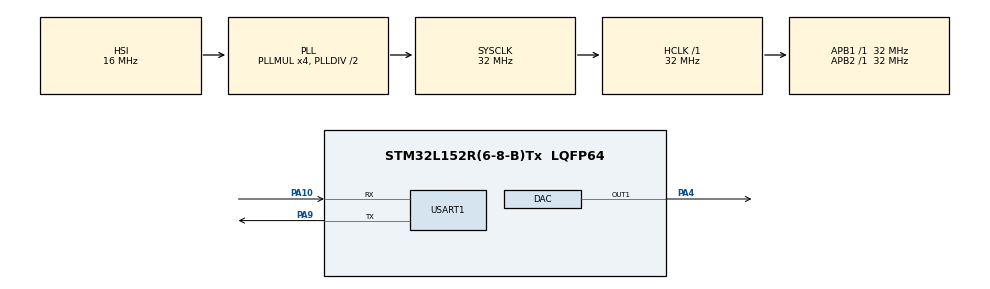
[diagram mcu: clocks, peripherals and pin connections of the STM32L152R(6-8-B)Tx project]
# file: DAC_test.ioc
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DAC.DAC_Trigger=DAC_TRIGGER_T6_TRGO
DAC.WaveGeneration=DISABLE
Dma.DAC_CH1.0.Direction=DMA_MEMORY_TO_PERIPH
Dma.DAC_CH1.0.Instance=DMA1_Channel2
Dma.DAC_CH1.0.MemDataAlignment=DMA_MDATAALIGN_HALFWORD
Dma.DAC_CH1.0.MemInc=DMA_MINC_ENABLE
Dma.DAC_CH1.0.Mode=DMA_CIRCULAR
Dma.DAC_CH1.0.PeriphDataAlignment=DMA_PDATAALIGN_HALFWORD
Dma.DAC_CH1.0.PeriphInc=DMA_PINC_DISABLE
Dma.DAC_CH1.0.Priority=DMA_PRIORITY_MEDIUM
Dma.Request0=DAC_CH1
Mcu.Family=STM32L1
Mcu.Name=STM32L152R(6-8-B)Tx
Mcu.Package=LQFP64
NVIC.DMA1_Channel2_IRQn=true\:0\:0\:false\:false\:true\:false
NVIC.PriorityGroup=NVIC_PRIORITYGROUP_4
NVIC.USART1_IRQn=true\:0\:0\:false\:false\:true\:true
PA10.Mode=Asynchronous
PA10.Signal=USART1_RX
PA13.Mode=Serial_Wire
PA13.Signal=SYS_JTMS-SWDIO
PA14.Mode=Serial_Wire
PA14.Signal=SYS_JTCK-SWCLK
PA4.Signal=COMP_DAC1_group
PA9.Mode=Asynchronous
PA9.Signal=USART1_TX
PH0-OSC_IN.Mode=HSE-External-Oscillator
PH0-OSC_IN.Signal=RCC_OSC_IN
PH1-OSC_OUT.Mode=HSE-External-Oscillator
PH1-OSC_OUT.Signal=RCC_OSC_OUT
ProjectManager.HeapSize=0x200
ProjectManager.StackSize=0x400
ProjectManager.TargetToolchain=TrueSTUDIO
RCC.48MHZClocksFreq_Value=32000000
RCC.AHBFreq_Value=32000000
RCC.APB1Freq_Value=32000000
RCC.APB1TimFreq_Value=32000000
RCC.APB2Freq_Value=32000000
RCC.APB2TimFreq_Value=32000000
RCC.HCLKFreq_Value=32000000
RCC.HSE_VALUE=8000000
RCC.HSI_VALUE=16000000
RCC.LSE_VALUE=32768
RCC.MSI_VALUE=2097000
RCC.PLLMUL=RCC_PLL_MUL4
RCC.SYSCLKFreq_VALUE=32000000
RCC.SYSCLKSource=RCC_SYSCLKSOURCE_PLLCLK
RCC.VCOOutputFreq_Value=64000000
SH.COMP_DAC1_group.0=DAC_OUT1,DAC_OUT1
TIM6.Period=720
TIM6.TIM_MasterOutputTrigger=TIM_TRGO_UPDATE
USART1.VirtualMode=VM_ASYNC
VP_TIM6_VS_ClockSourceINT.Mode=Enable_Timer
board=DAC_test

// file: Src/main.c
/**
  ******************************************************************************
  * File Name          : main.c
  * Description        : Main program body
  ******************************************************************************
  ** This notice applies to any and all portions of this file
  * that are not between comment pairs USER CODE BEGIN and
  * USER CODE END. Other portions of this file, whether
  * inserted by the user or by software development tools
  * are owned by their respective copyright owners.
  *
  * COPYRIGHT(c) 2018 STMicroelectronics
  *
  * Redistribution and use in source and binary forms, with or without modification,
  * are permitted provided that the following conditions are met:
  *   1. Redistributions of source code must retain the above copyright notice,
  *      this list of conditions and the following disclaimer.
  *   2. Redistributions in binary form must reproduce the above copyright notice,
  *      this list of conditions and the following disclaimer in the documentation
  *      and/or other materials provided with the distribution.
  *   3. Neither the name of STMicroelectronics nor the names of its contributors
  *      may be used to endorse or promote products derived from this software
  *      without specific prior written permission.
  *
  * THIS SOFTWARE IS PROVIDED BY THE COPYRIGHT HOLDERS AND CONTRIBUTORS "AS IS"
  * AND ANY EXPRESS OR IMPLIED WARRANTIES, INCLUDING, BUT NOT LIMITED TO, THE
  * IMPLIED WARRANTIES OF MERCHANTABILITY AND FITNESS FOR A PARTICULAR PURPOSE ARE
  * DISCLAIMED. IN NO EVENT SHALL THE COPYRIGHT HOLDER OR CONTRIBUTORS BE LIABLE
  * FOR ANY DIRECT, INDIRECT, INCIDENTAL, SPECIAL, EXEMPLARY, OR CONSEQUENTIAL
  * DAMAGES (INCLUDING, BUT NOT LIMITED TO, PROCUREMENT OF SUBSTITUTE GOODS OR
  * SERVICES; LOSS OF USE, DATA, OR PROFITS; OR BUSINESS INTERRUPTION) HOWEVER
  * CAUSED AND ON ANY THEORY OF LIABILITY, WHETHER IN CONTRACT, STRICT LIABILITY,
  * OR TORT (INCLUDING NEGLIGENCE OR OTHERWISE) ARISING IN ANY WAY OUT OF THE USE
  * OF THIS SOFTWARE, EVEN IF ADVISED OF THE POSSIBILITY OF SUCH DAMAGE.
  *
  ******************************************************************************
  */

#include "main.h"
#include "stm32l1xx_hal.h"

/* USER CODE BEGIN Includes */
#include <math.h>
/* USER CODE END Includes */

DAC_HandleTypeDef hdac;
DMA_HandleTypeDef hdma_dac_ch1;

TIM_HandleTypeDef htim6;

UART_HandleTypeDef huart1;

/* USER CODE BEGIN PV */
/* Private variables ---------------------------------------------------------*/

/* USER CODE END PV */

void SystemClock_Config(void);
static void MX_GPIO_Init(void);
static void MX_DMA_Init(void);
static void MX_USART1_UART_Init(void);
static void MX_DAC_Init(void);
static void MX_TIM6_Init(void);

/* USER CODE BEGIN PFP */
/* Private function prototypes -----------------------------------------------*/

/* USER CODE END PFP */

/* USER CODE BEGIN 0 */
uint16_t buf_tr[128];
/*uint16_t buf_tr[64]={
					127,255,383,511,639,767,895,1023,
					1151,1279,1407,1535,1663,1791,1919,2047,
					2175,2303,2431,2559,2687,2815,2943,3071,
					3199,3327,3455,3583,3711,3839,3967,4095,
					3967,3839,3711,3583,3455,3327,3199,3071,
					2943,2815,2687,2559,2431,2303,2175,2047,
					1919,1791,1663,1535,1407,1279,1151,1023,
					895,767,639,511,383,255,127,0
					};*/
/* USER CODE END 0 */

int main(void)
{

  /* USER CODE BEGIN 1 */
	int bv = 0;
	for (int i=0; i<128; i++)
	{
		bv = (int)((1.0 + sin(((float)i)*M_PI/64))*2048);
		if (bv>=4095) bv = 4095;
		if (bv<=0) bv = 0;
		buf_tr[i] = (uint32_t)bv;
	}
  /* USER CODE END 1 */

  /* MCU Configuration----------------------------------------------------------*/

  /* Reset of all peripherals, Initializes the Flash interface and the Systick. */
  HAL_Init();

  /* Configure the system clock */
  SystemClock_Config();

  /* Initialize all configured peripherals */
  MX_GPIO_Init();
  MX_DMA_Init();
  MX_USART1_UART_Init();
  MX_DAC_Init();
  MX_TIM6_Init();

  /* USER CODE BEGIN 2 */
  HAL_TIM_Base_Start(&htim6);
  HAL_DAC_Start_DMA(&hdac, DAC_CHANNEL_1, (uint32_t*)buf_tr, 128, DAC_ALIGN_12B_R);
  /* USER CODE END 2 */

  /* Infinite loop */
  while (1)
  {

  }

}

/** System Clock Configuration
*/
void SystemClock_Config(void)
{

  RCC_OscInitTypeDef RCC_OscInitStruct;
  RCC_ClkInitTypeDef RCC_ClkInitStruct;

    /**Configure the main internal regulator output voltage
    */
  __HAL_PWR_VOLTAGESCALING_CONFIG(PWR_REGULATOR_VOLTAGE_SCALE1);

    /**Initializes the CPU, AHB and APB busses clocks
    */
  RCC_OscInitStruct.OscillatorType = RCC_OSCILLATORTYPE_HSI;
  RCC_OscInitStruct.HSIState = RCC_HSI_ON;
  RCC_OscInitStruct.HSICalibrationValue = 16;
  RCC_OscInitStruct.PLL.PLLState = RCC_PLL_ON;
  RCC_OscInitStruct.PLL.PLLSource = RCC_PLLSOURCE_HSI;
  RCC_OscInitStruct.PLL.PLLMUL = RCC_PLL_MUL4;
  RCC_OscInitStruct.PLL.PLLDIV = RCC_PLL_DIV2;
  if (HAL_RCC_OscConfig(&RCC_OscInitStruct) != HAL_OK)
  {
    _Error_Handler(__FILE__, __LINE__);
  }

    /**Initializes the CPU, AHB and APB busses clocks
    */
  RCC_ClkInitStruct.ClockType = RCC_CLOCKTYPE_HCLK|RCC_CLOCKTYPE_SYSCLK
                              |RCC_CLOCKTYPE_PCLK1|RCC_CLOCKTYPE_PCLK2;
  RCC_ClkInitStruct.SYSCLKSource = RCC_SYSCLKSOURCE_PLLCLK;
  RCC_ClkInitStruct.AHBCLKDivider = RCC_SYSCLK_DIV1;
  RCC_ClkInitStruct.APB1CLKDivider = RCC_HCLK_DIV1;
  RCC_ClkInitStruct.APB2CLKDivider = RCC_HCLK_DIV1;

  if (HAL_RCC_ClockConfig(&RCC_ClkInitStruct, FLASH_LATENCY_1) != HAL_OK)
  {
    _Error_Handler(__FILE__, __LINE__);
  }

    /**Configure the Systick interrupt time
    */
  HAL_SYSTICK_Config(HAL_RCC_GetHCLKFreq()/1000);

    /**Configure the Systick
    */
  HAL_SYSTICK_CLKSourceConfig(SYSTICK_CLKSOURCE_HCLK);

  /* SysTick_IRQn interrupt configuration */
  HAL_NVIC_SetPriority(SysTick_IRQn, 0, 0);
}

/* DAC init function */
static void MX_DAC_Init(void)
{

  DAC_ChannelConfTypeDef sConfig;

    /**DAC Initialization
    */
  hdac.Instance = DAC;
  if (HAL_DAC_Init(&hdac) != HAL_OK)
  {
    _Error_Handler(__FILE__, __LINE__);
  }

    /**DAC channel OUT1 config
    */
  sConfig.DAC_Trigger = DAC_TRIGGER_T6_TRGO;
  sConfig.DAC_OutputBuffer = DAC_OUTPUTBUFFER_ENABLE;
  if (HAL_DAC_ConfigChannel(&hdac, &sConfig, DAC_CHANNEL_1) != HAL_OK)
  {
    _Error_Handler(__FILE__, __LINE__);
  }

}

/* TIM6 init function */
static void MX_TIM6_Init(void)
{

  TIM_MasterConfigTypeDef sMasterConfig;

  htim6.Instance = TIM6;
  htim6.Init.Prescaler = 0;
  htim6.Init.CounterMode = TIM_COUNTERMODE_UP;
  htim6.Init.Period = 720;
  if (HAL_TIM_Base_Init(&htim6) != HAL_OK)
  {
    _Error_Handler(__FILE__, __LINE__);
  }

  sMasterConfig.MasterOutputTrigger = TIM_TRGO_UPDATE;
  sMasterConfig.MasterSlaveMode = TIM_MASTERSLAVEMODE_DISABLE;
  if (HAL_TIMEx_MasterConfigSynchronization(&htim6, &sMasterConfig) != HAL_OK)
  {
    _Error_Handler(__FILE__, __LINE__);
  }

}

/* USART1 init function */
static void MX_USART1_UART_Init(void)
{

  huart1.Instance = USART1;
  huart1.Init.BaudRate = 115200;
  huart1.Init.WordLength = UART_WORDLENGTH_8B;
  huart1.Init.StopBits = UART_STOPBITS_1;
  huart1.Init.Parity = UART_PARITY_NONE;
  huart1.Init.Mode = UART_MODE_TX_RX;
  huart1.Init.HwFlowCtl = UART_HWCONTROL_NONE;
  huart1.Init.OverSampling = UART_OVERSAMPLING_16;
  if (HAL_UART_Init(&huart1) != HAL_OK)
  {
    _Error_Handler(__FILE__, __LINE__);
  }

}

static void MX_DMA_Init(void)
{
  /* DMA controller clock enable */
  __HAL_RCC_DMA1_CLK_ENABLE();

  /* DMA interrupt init */
  /* DMA1_Channel2_IRQn interrupt configuration */
  HAL_NVIC_SetPriority(DMA1_Channel2_IRQn, 0, 0);
  HAL_NVIC_EnableIRQ(DMA1_Channel2_IRQn);

}

/** Configure pins as
        * Analog
        * Input
        * Output
        * EVENT_OUT
        * EXTI
*/
static void MX_GPIO_Init(void)
{

  /* GPIO Ports Clock Enable */
  __HAL_RCC_GPIOH_CLK_ENABLE();
  __HAL_RCC_GPIOA_CLK_ENABLE();

}

void _Error_Handler(char * file, int line)
{
  while(1)
  {
  }
}

/************************ (C) COPYRIGHT STMicroelectronics *****END OF FILE****/
